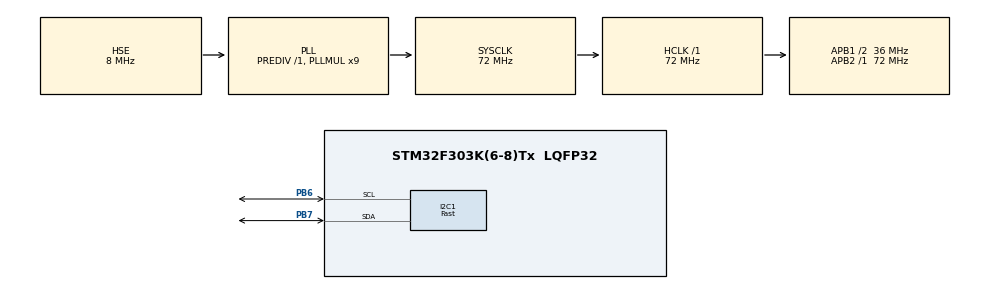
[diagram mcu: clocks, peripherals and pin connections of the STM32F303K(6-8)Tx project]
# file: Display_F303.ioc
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I2C1.I2C_Speed_Mode=I2C_Fast
I2C1.Speed=400
I2C1.Timing=0x0000020B
Mcu.Family=STM32F3
Mcu.Name=STM32F303K(6-8)Tx
Mcu.Package=LQFP32
NVIC.PriorityGroup=NVIC_PRIORITYGROUP_4
PA13.Mode=Serial_Wire
PA13.Signal=SYS_JTMS-SWDIO
PA14.Mode=Serial_Wire
PA14.Signal=SYS_JTCK-SWCLK
PB6.Mode=I2C
PB6.Signal=I2C1_SCL
PB7.Mode=I2C
PB7.Signal=I2C1_SDA
PF0\ /\ OSC_IN.Mode=HSE-External-Clock-Source
PF0\ /\ OSC_IN.Signal=RCC_OSC_IN
ProjectManager.HeapSize=0x200
ProjectManager.StackSize=0x400
ProjectManager.TargetToolchain=STM32CubeIDE
RCC.AHBFreq_Value=72000000
RCC.APB1CLKDivider=RCC_HCLK_DIV2
RCC.APB1Freq_Value=36000000
RCC.APB1TimFreq_Value=72000000
RCC.APB2Freq_Value=72000000
RCC.APB2TimFreq_Value=72000000
RCC.CortexFreq_Value=72000000
RCC.HCLKFreq_Value=72000000
RCC.HSE_VALUE=8000000
RCC.HSI_VALUE=8000000
RCC.PLLMUL=RCC_PLL_MUL9
RCC.PLLSourceVirtual=RCC_PLLSOURCE_HSE
RCC.SYSCLKFreq_VALUE=72000000
RCC.SYSCLKSourceVirtual=RCC_SYSCLKSOURCE_PLLCLK
board=custom

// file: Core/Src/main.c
/* USER CODE BEGIN Header */
/**
 ******************************************************************************
 * @file           : main.c
 * @brief          : Main program body
 ******************************************************************************
 * @attention
 *
 * <h2><center>&copy; Copyright (c) 2020 STMicroelectronics.
 * All rights reserved.</center></h2>
 *
 * This software component is licensed by ST under BSD 3-Clause license,
 * the "License"; You may not use this file except in compliance with the
 * License. You may obtain a copy of the License at:
 *                        opensource.org/licenses/BSD-3-Clause
 *
 ******************************************************************************
 */
/* USER CODE END Header */

#include "main.h"

/* USER CODE BEGIN Includes */
#include "ssd1306.h"
/* USER CODE END Includes */

I2C_HandleTypeDef hi2c1;

/* USER CODE BEGIN PV */

const uint8_t ayb[] = { 0x00, 0x00, 0xfc, 0xfc, 0x0c, 0x0c, 0x0c, 0x8c, 0x8c,
		0x8e, 0x8e, 0xc7, 0xc3, 0x63, 0x71, 0x70, 0x70, 0xe1, 0xc3, 0xc3, 0xc7,
		0xcf, 0xce, 0xcc, 0x8c, 0x0c, 0x0c, 0x0c, 0xfc, 0xfc, 0x00, 0x00, 0xf0,
		0x38, 0x1f, 0x0f, 0x00, 0xc0, 0xf0, 0x3f, 0x0f, 0x01, 0x81, 0xf1, 0x78,
		0x18, 0x18, 0x8c, 0x9c, 0x18, 0x18, 0x78, 0xf0, 0xc0, 0x81, 0x07, 0x1f,
		0x78, 0xe0, 0xc0, 0x07, 0x0f, 0x1e, 0x7c, 0x0f, 0x1e, 0x78, 0xf0, 0xc0,
		0x07, 0x0f, 0xfc, 0xf0, 0x80, 0x83, 0x1f, 0x1c, 0x18, 0x18, 0x39, 0x1f,
		0x8f, 0x80, 0xc0, 0xfc, 0xff, 0x07, 0x01, 0x00, 0xf0, 0xfc, 0x1f, 0x07,
		0xc0, 0xf0, 0xfc, 0x00, 0x00, 0x00, 0x3f, 0x3f, 0x38, 0x38, 0x31, 0x31,
		0x31, 0x73, 0xe3, 0xe3, 0xc3, 0x87, 0x0e, 0x87, 0xc3, 0xe1, 0xf1, 0x30,
		0x38, 0x18, 0x1c, 0x1f, 0x0f, 0x83, 0xc0, 0xc0, 0xff, 0xff, 0xff };

const Image aybImage = { .width = 32, .height = 32, .data = ayb };
/* USER CODE END PV */

void SystemClock_Config(void);
static void MX_GPIO_Init(void);
static void MX_I2C1_Init(void);

int main(void)
{

  /* MCU Configuration--------------------------------------------------------*/

  /* Reset of all peripherals, Initializes the Flash interface and the Systick. */
  HAL_Init();

  /* Configure the system clock */
  SystemClock_Config();

  /* Initialize all configured peripherals */
  MX_GPIO_Init();
  MX_I2C1_Init();

  /* Infinite loop */
  /* USER CODE BEGIN WHILE */
	ssd1306_Init();
	uint8_t position = 0;
	int8_t velocity = 1;
	while (1) {

		ssd1306_Fill(Black);
		ssd1306_SetCursor(position % 128, 12);
		ssd1306_DrawImage(aybImage, White);
		ssd1306_SetCursor(position % 128, 12 + 32);
		ssd1306_WriteString("AYB", Font_11x18, White);
		ssd1306_UpdateScreen();
		position += velocity;
		if (position >= 128 - 33 || position == 0)
			velocity *= -1;
    /* USER CODE END WHILE */

	}
}

void SystemClock_Config(void)
{
  RCC_OscInitTypeDef RCC_OscInitStruct = {0};
  RCC_ClkInitTypeDef RCC_ClkInitStruct = {0};
  RCC_PeriphCLKInitTypeDef PeriphClkInit = {0};

  /** Initializes the CPU, AHB and APB busses clocks
  */
  RCC_OscInitStruct.OscillatorType = RCC_OSCILLATORTYPE_HSI|RCC_OSCILLATORTYPE_HSE;
  RCC_OscInitStruct.HSEState = RCC_HSE_BYPASS;
  RCC_OscInitStruct.HSEPredivValue = RCC_HSE_PREDIV_DIV1;
  RCC_OscInitStruct.HSIState = RCC_HSI_ON;
  RCC_OscInitStruct.HSICalibrationValue = RCC_HSICALIBRATION_DEFAULT;
  RCC_OscInitStruct.PLL.PLLState = RCC_PLL_ON;
  RCC_OscInitStruct.PLL.PLLSource = RCC_PLLSOURCE_HSE;
  RCC_OscInitStruct.PLL.PLLMUL = RCC_PLL_MUL9;
  if (HAL_RCC_OscConfig(&RCC_OscInitStruct) != HAL_OK)
  {
    Error_Handler();
  }
  /** Initializes the CPU, AHB and APB busses clocks
  */
  RCC_ClkInitStruct.ClockType = RCC_CLOCKTYPE_HCLK|RCC_CLOCKTYPE_SYSCLK
                              |RCC_CLOCKTYPE_PCLK1|RCC_CLOCKTYPE_PCLK2;
  RCC_ClkInitStruct.SYSCLKSource = RCC_SYSCLKSOURCE_PLLCLK;
  RCC_ClkInitStruct.AHBCLKDivider = RCC_SYSCLK_DIV1;
  RCC_ClkInitStruct.APB1CLKDivider = RCC_HCLK_DIV2;
  RCC_ClkInitStruct.APB2CLKDivider = RCC_HCLK_DIV1;

  if (HAL_RCC_ClockConfig(&RCC_ClkInitStruct, FLASH_LATENCY_2) != HAL_OK)
  {
    Error_Handler();
  }
  PeriphClkInit.PeriphClockSelection = RCC_PERIPHCLK_I2C1;
  PeriphClkInit.I2c1ClockSelection = RCC_I2C1CLKSOURCE_HSI;
  if (HAL_RCCEx_PeriphCLKConfig(&PeriphClkInit) != HAL_OK)
  {
    Error_Handler();
  }
}

static void MX_I2C1_Init(void)
{

  hi2c1.Instance = I2C1;
  hi2c1.Init.Timing = 0x0000020B;
  hi2c1.Init.OwnAddress1 = 0;
  hi2c1.Init.AddressingMode = I2C_ADDRESSINGMODE_7BIT;
  hi2c1.Init.DualAddressMode = I2C_DUALADDRESS_DISABLE;
  hi2c1.Init.OwnAddress2 = 0;
  hi2c1.Init.OwnAddress2Masks = I2C_OA2_NOMASK;
  hi2c1.Init.GeneralCallMode = I2C_GENERALCALL_DISABLE;
  hi2c1.Init.NoStretchMode = I2C_NOSTRETCH_DISABLE;
  if (HAL_I2C_Init(&hi2c1) != HAL_OK)
  {
    Error_Handler();
  }
  /** Configure Analogue filter
  */
  if (HAL_I2CEx_ConfigAnalogFilter(&hi2c1, I2C_ANALOGFILTER_ENABLE) != HAL_OK)
  {
    Error_Handler();
  }
  /** Configure Digital filter
  */
  if (HAL_I2CEx_ConfigDigitalFilter(&hi2c1, 0) != HAL_OK)
  {
    Error_Handler();
  }

}

static void MX_GPIO_Init(void)
{

  /* GPIO Ports Clock Enable */
  __HAL_RCC_GPIOF_CLK_ENABLE();
  __HAL_RCC_GPIOA_CLK_ENABLE();
  __HAL_RCC_GPIOB_CLK_ENABLE();

}

void Error_Handler(void)
{
}

/************************ (C) COPYRIGHT STMicroelectronics *****END OF FILE****/
